# ESP32S31_RADIO register map
Vendor: Espressif; Series: ESP32-S31; File version: 3.52
Registers are 32-bit, read-write, no defined reset value unless marked. A register's access mark holds for its fields unless they carry their own. Offsets are from the block's base; [hi:lo] are bit positions.

## WIFI_MAC_POWER_INTERRUPT — WDEVPWR interrupt bank named by complete print_isr_regs. Complete hal_pwr_interrupt_get_event and hal_pwr_interrupt_clr_event independently prove the masked STATUS read and full-width CLEAR acknowledgement transaction. Complete TSF timer enable/disable leaves update the timer interrupt masks in ENABLE and clear stale events through CLEAR.
Base 0x2010D8B4
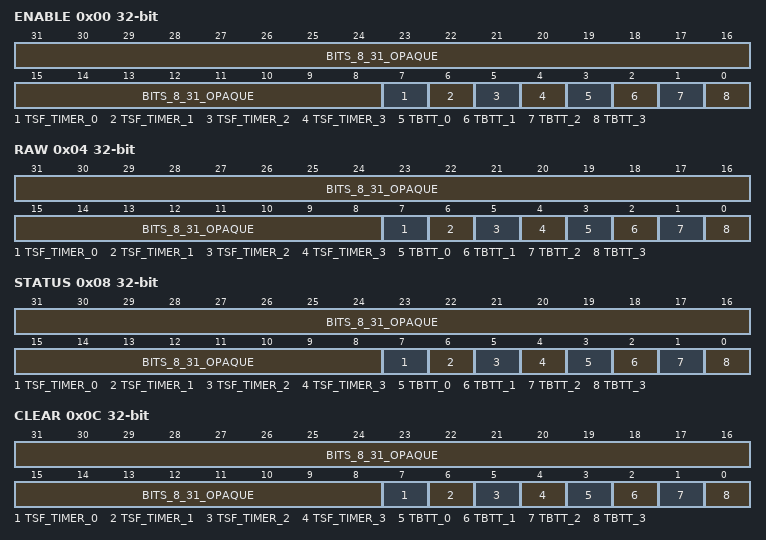
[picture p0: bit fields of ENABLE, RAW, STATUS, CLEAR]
0x00 ENABLE — Project-assigned name. WDEVPWR_ENABLE diagnostic snapshot and writable event mask. Complete guarded TSF-timer leaves independently identify bits 7 through 4, and complete TBTT interrupt leaves bits 3 through 0.
  [31:8] BITS_8_31_OPAQUE — Opaque: meaning not established. Enable bits whose event identities remain unknown.
  [7] TSF_TIMER_0 — Project-assigned name. Enable the guarded TSF timer-zero event.
  [6] TSF_TIMER_1 — Project-assigned name. Enable the guarded TSF timer-one event.
  [5] TSF_TIMER_2 — Project-assigned name. Enable the guarded TSF timer-two event.
  [4] TSF_TIMER_3 — Project-assigned name. Enable the guarded TSF timer-three event.
  [3] TBTT_0 — Project-assigned name. Enable the TSF-0 TBTT event. TSF 0 is the station TSF.
  [2] TBTT_1 — Project-assigned name. Enable the TSF-1 TBTT event.
  [1] TBTT_2 — Project-assigned name. Enable the TSF-2 TBTT event.
  [0] TBTT_3 — Project-assigned name. Enable the TSF-3 TBTT event.
0x04 RAW ro — Project-assigned name. WDEVPWR_RAW diagnostic snapshot with the same event geometry as ENABLE, STATUS and CLEAR.
  [31:8] BITS_8_31_OPAQUE — Opaque: meaning not established. Raw event bits whose identities remain unknown.
  [7] TSF_TIMER_0 — Project-assigned name. Raw guarded TSF timer-zero event.
  [6] TSF_TIMER_1 — Project-assigned name. Raw guarded TSF timer-one event.
  [5] TSF_TIMER_2 — Project-assigned name. Raw guarded TSF timer-two event.
  [4] TSF_TIMER_3 — Project-assigned name. Raw guarded TSF timer-three event.
  [3] TBTT_0 — Project-assigned name. Raw TSF-0 TBTT event. TSF 0 is the station TSF.
  [2] TBTT_1 — Project-assigned name. Raw TSF-1 TBTT event.
  [1] TBTT_2 — Project-assigned name. Raw TSF-2 TBTT event.
  [0] TBTT_3 — Project-assigned name. Raw TSF-3 TBTT event.
0x08 STATUS ro — Project-assigned name. Masked WDEVPWR event image returned by complete hal_pwr_interrupt_get_event, with TSF timer causes identified by the guarded timer leaves.
  [31:8] BITS_8_31_OPAQUE — Opaque: meaning not established. Masked event bits whose identities remain unknown.
  [7] TSF_TIMER_0 — Project-assigned name. Masked guarded TSF timer-zero event.
  [6] TSF_TIMER_1 — Project-assigned name. Masked guarded TSF timer-one event.
  [5] TSF_TIMER_2 — Project-assigned name. Masked guarded TSF timer-two event.
  [4] TSF_TIMER_3 — Project-assigned name. Masked guarded TSF timer-three event.
  [3] TBTT_0 — Project-assigned name. Masked TSF-0 TBTT event. TSF 0 is the station TSF.
  [2] TBTT_1 — Project-assigned name. Masked TSF-1 TBTT event.
  [1] TBTT_2 — Project-assigned name. Masked TSF-2 TBTT event.
  [0] TBTT_3 — Project-assigned name. Masked TSF-3 TBTT event.
0x0C CLEAR write-1-clears — Project-assigned name. Write-one-to-clear event bank used by complete hal_pwr_interrupt_clr_event. Complete guarded TSF-timer leaves independently identify bits 7 through 4.
  [31:8] BITS_8_31_OPAQUE — Opaque: meaning not established. Acknowledge event bits whose identities remain unknown.
  [7] TSF_TIMER_0 — Project-assigned name. Acknowledge the guarded TSF timer-zero event.
  [6] TSF_TIMER_1 — Project-assigned name. Acknowledge the guarded TSF timer-one event.
  [5] TSF_TIMER_2 — Project-assigned name. Acknowledge the guarded TSF timer-two event.
  [4] TSF_TIMER_3 — Project-assigned name. Acknowledge the guarded TSF timer-three event.
  [3] TBTT_0 — Project-assigned name. Acknowledge the TSF-0 TBTT event. TSF 0 is the station TSF.
  [2] TBTT_1 — Project-assigned name. Acknowledge the TSF-1 TBTT event.
  [1] TBTT_2 — Project-assigned name. Acknowledge the TSF-2 TBTT event.
  [0] TBTT_3 — Project-assigned name. Acknowledge the TSF-3 TBTT event.
